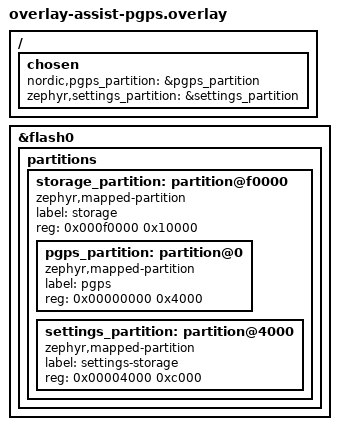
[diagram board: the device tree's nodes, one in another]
/*
 * Copyright (c) 2026 Nordic Semiconductor ASA
 *
 * SPDX-License-Identifier: LicenseRef-Nordic-5-Clause
 */

/*
 * Carve a P-GPS partition out of the 64 kB storage area (0xF0000).
 *
 * Flash layout (storage area):
 *   0x000F_0000  P-GPS partition   (16 kB, 8 predictions × 2 kB)
 *   0x000F_4000  Settings storage  (48 kB)
 */

/ {
	chosen {
		nordic,pgps_partition = &pgps_partition;
		zephyr,settings_partition = &settings_partition;
	};
};

/delete-node/ &storage_partition;

&flash0 {
	partitions {
		storage_partition: partition@f0000 {
			compatible = "zephyr,mapped-partition";
			label = "storage";
			reg = <0x000f0000 0x10000>;
			ranges = <0x0 0x000f0000 0x10000>;
			#address-cells = <1>;
			#size-cells = <1>;

			pgps_partition: partition@0 {
				compatible = "zephyr,mapped-partition";
				label = "pgps";
				reg = <0x00000000 0x4000>;
			};

			settings_partition: partition@4000 {
				compatible = "zephyr,mapped-partition";
				label = "settings-storage";
				reg = <0x00004000 0xc000>;
			};
		};
	};
};
